VERSION ""

NS_ :

BS_:

BU_: EPS ESP_ECU BCM VCU MPC_CAM ADAS_ECU MCU BSD

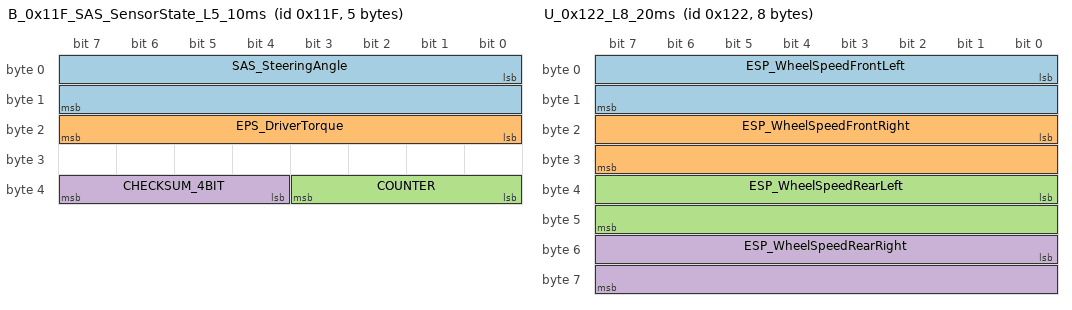
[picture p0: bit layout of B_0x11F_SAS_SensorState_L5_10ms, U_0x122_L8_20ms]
BO_ 287 B_0x11F_SAS_SensorState_L5_10ms: 5 EPS
 SG_ SAS_SteeringAngle : 0|16@1- (0.1,0) [-780|780] "deg" MCU,ADAS_ECU
 SG_ EPS_DriverTorque : 16|8@1+ (1,0) [0|255] "" MCU,ADAS_ECU
 SG_ COUNTER : 35|4@0+ (1,0) [0|15] "" MCU
 SG_ CHECKSUM_4BIT : 39|4@0+ (1,0) [0|15] "" MCU

BO_ 290 U_0x122_L8_20ms: 8 ESP_ECU
 SG_ ESP_WheelSpeedFrontLeft : 0|16@1+ (0.1,0) [0|6553.5] "kph" MCU,ADAS_ECU
 SG_ ESP_WheelSpeedFrontRight : 16|16@1+ (0.1,0) [0|6553.5] "kph" MCU,ADAS_ECU
 SG_ ESP_WheelSpeedRearLeft : 32|16@1+ (0.1,0) [0|6553.5] "kph" MCU,ADAS_ECU
 SG_ ESP_WheelSpeedRearRight : 48|16@1+ (0.1,0) [0|6553.5] "kph" MCU,ADAS_ECU

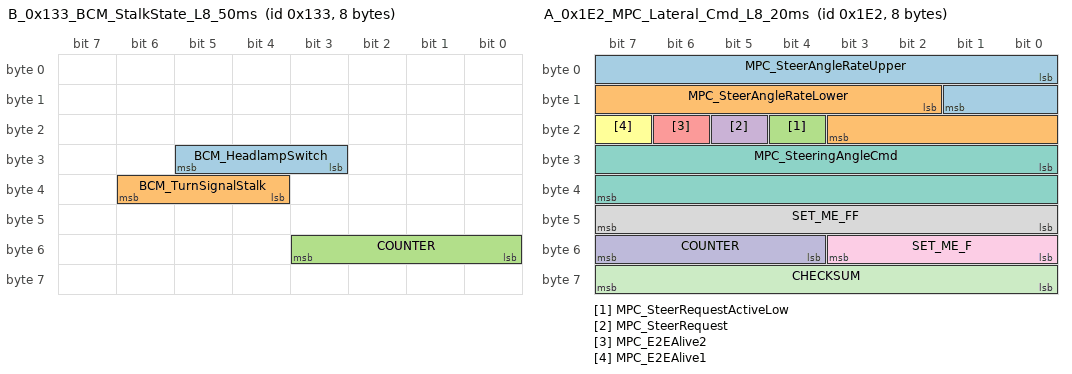
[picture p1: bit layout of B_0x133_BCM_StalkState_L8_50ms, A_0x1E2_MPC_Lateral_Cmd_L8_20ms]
BO_ 307 B_0x133_BCM_StalkState_L8_50ms: 8 BCM
 SG_ BCM_HeadlampSwitch : 27|3@1+ (1,0) [0|7] "" MCU
 SG_ BCM_TurnSignalStalk : 36|3@1+ (1,0) [0|7] "" MCU
 SG_ COUNTER : 48|4@1+ (1,0) [0|15] "" MCU

BO_ 482 A_0x1E2_MPC_Lateral_Cmd_L8_20ms: 8 ADAS_ECU
 SG_ MPC_SteerAngleRateUpper : 0|10@1- (1,0) [-512|511] "" EPS
 SG_ MPC_SteerAngleRateLower : 10|10@1- (1,0) [-512|511] "" EPS
 SG_ MPC_SteerRequestActiveLow : 20|1@1+ (1,0) [0|1] "" EPS
 SG_ MPC_SteerRequest : 21|1@1+ (1,0) [0|1] "" EPS
 SG_ MPC_E2EAlive2 : 22|1@1+ (1,0) [0|1] "" EPS
 SG_ MPC_E2EAlive1 : 23|1@1+ (1,0) [0|1] "" EPS
 SG_ MPC_SteeringAngleCmd : 24|16@1- (0.1,0) [-3276.8|3276.7] "deg" EPS
 SG_ SET_ME_FF : 40|8@1+ (1,0) [0|255] "" EPS
 SG_ SET_ME_F : 48|4@1+ (1,0) [0|15] "" EPS
 SG_ COUNTER : 52|4@1+ (1,0) [0|15] "" EPS
 SG_ CHECKSUM : 56|8@1+ (1,0) [0|255] "" EPS

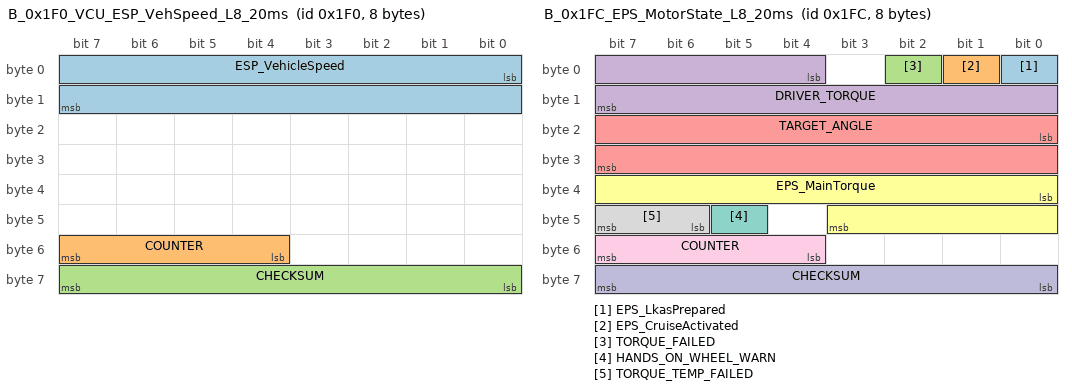
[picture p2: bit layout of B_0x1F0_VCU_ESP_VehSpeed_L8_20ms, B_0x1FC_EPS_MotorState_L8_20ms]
BO_ 496 B_0x1F0_VCU_ESP_VehSpeed_L8_20ms: 8 ESP_ECU
 SG_ ESP_VehicleSpeed : 0|16@1+ (0.07142857,0) [0|4681.16505] "kph" MCU
 SG_ COUNTER : 55|4@0+ (1,0) [0|15] "" MCU
 SG_ CHECKSUM : 56|8@1+ (1,0) [0|255] "" MCU

BO_ 508 B_0x1FC_EPS_MotorState_L8_20ms: 8 EPS
 SG_ EPS_LkasPrepared : 0|1@1+ (1,0) [0|1] "" MCU,ADAS_ECU
 SG_ EPS_CruiseActivated : 1|1@1+ (1,0) [0|1] "" MCU,ADAS_ECU
 SG_ TORQUE_FAILED : 2|1@1+ (1,0) [0|1] "" MCU,ADAS_ECU
 SG_ DRIVER_TORQUE : 4|12@1- (0.1,0) [-204.8|204.7] "Nm" MCU,ADAS_ECU
 SG_ TARGET_ANGLE : 16|16@1- (0.1,0) [-3276.8|3276.7] "deg" MCU,ADAS_ECU
 SG_ EPS_MainTorque : 32|12@1- (1,0) [-2048|2047] "" MCU,ADAS_ECU
 SG_ HANDS_ON_WHEEL_WARN : 45|1@1+ (1,0) [0|1] "" MCU,ADAS_ECU
 SG_ TORQUE_TEMP_FAILED : 46|2@1+ (1,0) [0|3] "" MCU,ADAS_ECU
 SG_ COUNTER : 52|4@1+ (1,0) [0|15] "" MCU
 SG_ CHECKSUM : 56|8@1+ (1,0) [0|255] "" MCU

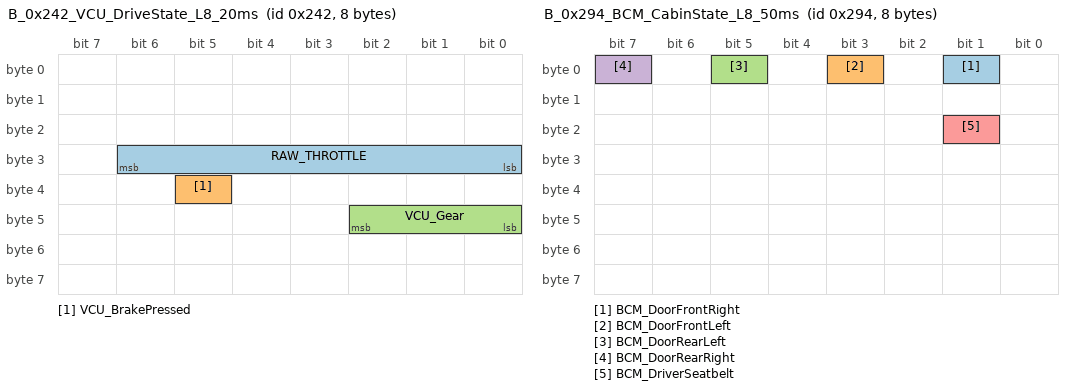
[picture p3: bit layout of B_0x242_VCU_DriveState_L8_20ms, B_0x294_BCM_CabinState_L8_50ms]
BO_ 578 B_0x242_VCU_DriveState_L8_20ms: 8 VCU
 SG_ RAW_THROTTLE : 24|7@1+ (1,0) [0|127] "" MCU
 SG_ VCU_BrakePressed : 37|1@1+ (1,0) [0|1] "" MCU,ADAS_ECU
 SG_ VCU_Gear : 40|3@1+ (1,0) [0|7] "" MCU

BO_ 660 B_0x294_BCM_CabinState_L8_50ms: 8 BCM
 SG_ BCM_DoorFrontRight : 1|1@1+ (1,0) [0|1] "" MCU
 SG_ BCM_DoorFrontLeft : 3|1@1+ (1,0) [0|1] "" MCU
 SG_ BCM_DoorRearLeft : 5|1@1+ (1,0) [0|1] "" MCU
 SG_ BCM_DoorRearRight : 7|1@1+ (1,0) [0|1] "" MCU
 SG_ BCM_DriverSeatbelt : 17|1@1+ (1,0) [0|1] "" MCU

BO_ 790 A_0x316_MPC_MpcState_L8_20ms: 8 MPC_CAM
 SG_ AUTO_LIGHT : 1|2@0+ (1,0) [0|3] "" XXX
 SG_ MPC_HudPt1 : 2|2@1+ (1,0) [0|3] "" MCU
 SG_ MPC_LeftLaneState : 4|2@1+ (1,0) [0|3] "" MCU
 SG_ MPC_LksMode : 6|2@1+ (1,0) [0|3] "" MCU
 SG_ MPC_HudPt2 : 8|2@1+ (1,0) [0|3] "" MCU
 SG_ MPC_HandsOnWheelRequest : 10|1@1+ (1,0) [0|1] "" MCU
 SG_ MPC_TjaIcaState : 11|4@1+ (1,0) [0|15] "" MCU
 SG_ HMA_ON_OFF : 15|1@0+ (1,0) [0|1] "" MCU
 SG_ MPC_LkasOutput : 16|11@1- (1,0) [-1024|1023] "" MCU
 SG_ MPC_LkasRequestPrepare : 27|1@1+ (1,0) [0|1] "" MCU
 SG_ MPC_LkasActive : 28|1@1+ (1,0) [0|1] "" MCU
 SG_ MPC_SlaState : 29|3@1+ (1,0) [0|7] "" MCU
 SG_ MPC_HudPt3 : 32|2@1+ (1,0) [0|3] "" MCU
 SG_ MPC_RightLaneState : 34|2@1+ (1,0) [0|3] "" MCU
 SG_ MPC_LkasState : 36|4@1+ (1,0) [0|15] "" MCU
 SG_ MPC_SpeedLimitValue : 40|8@1+ (5,-5) [-5|1270] "kph" MCU
 SG_ LDSW_TYPE : 49|2@0+ (1,0) [0|3] "" MCU
 SG_ MPC_HudPt4 : 50|2@1+ (1,0) [0|3] "" MCU
 SG_ COUNTER : 52|4@1+ (1,0) [0|15] "" MCU
 SG_ CHECKSUM : 56|8@1+ (1,0) [0|255] "" MCU

BO_ 813 B_0x32D_HUD_AdasState_L8_20ms: 8 ADAS_ECU
 SG_ VCU_ACCSetSpeed : 0|8@1+ (0.5,0) [0|127.5] "kph" MCU
 SG_ VCU_ACCSetDistance : 10|3@1+ (1,0) [0|7] "" MCU
 SG_ VCU_ACCState : 19|3@1+ (1,0) [0|7] "" MCU
 SG_ ACC_ON2 : 20|1@0+ (1,0) [0|1] "" MCU
 SG_ ACC_ON1 : 22|1@0+ (1,0) [0|1] "" MCU
 SG_ SET_ME_XFF : 47|8@0+ (1,0) [0|255] "" MCU
 SG_ COUNTER : 48|4@1+ (1,0) [0|15] "" MCU
 SG_ SET_ME_XF : 55|4@0+ (1,0) [0|15] "" MCU
 SG_ CHECKSUM : 56|8@1+ (1,0) [0|255] "" MCU

BO_ 814 A_0x32E_MPC_Long_Cmd_L8_20ms: 8 ADAS_ECU
 SG_ MPC_AccelerationCmd : 0|8@1+ (0.05,-5) [-5|7.75] "m/s^2" MCU
 SG_ MPC_AccOnPrimary : 9|1@1+ (1,0) [0|1] "" MCU
 SG_ SET_ME_25_1 : 10|6@1+ (1,0) [0|63] "" MCU
 SG_ MPC_AccOnSecondary : 17|1@1+ (1,0) [0|1] "" MCU
 SG_ SET_ME_25_2 : 18|6@1+ (1,0) [0|63] "" MCU
 SG_ MPC_ComfortDecelFactor : 24|4@1+ (1,0) [0|15] "" MCU
 SG_ SET_ME_X8 : 28|4@1+ (1,0) [0|15] "" MCU
 SG_ MPC_ComfortAccelFactor : 32|4@1+ (1,0) [0|15] "" MCU
 SG_ MPC_CommandRequestActiveLow : 36|1@1+ (1,0) [0|1] "" MCU
 SG_ SET_ME_1 : 38|1@1+ (1,0) [0|1] "" MCU
 SG_ MPC_StandstillResume : 39|1@1+ (1,0) [0|1] "" MCU
 SG_ MPC_StandstillState : 40|1@1+ (1,0) [0|1] "" MCU
 SG_ MPC_AccRequestNotStandstill : 43|1@1+ (1,0) [0|1] "" MCU
 SG_ MPC_AccControllableOn : 44|1@1+ (1,0) [0|1] "" MCU
 SG_ MPC_AccOverrideStandstill : 45|1@1+ (1,0) [0|1] "" MCU
 SG_ COUNTER : 48|4@1+ (1,0) [0|15] "" MCU
 SG_ SET_ME_XF : 55|4@0+ (1,0) [0|15] "" MCU
 SG_ CHECKSUM : 56|8@1+ (1,0) [0|255] "" MCU

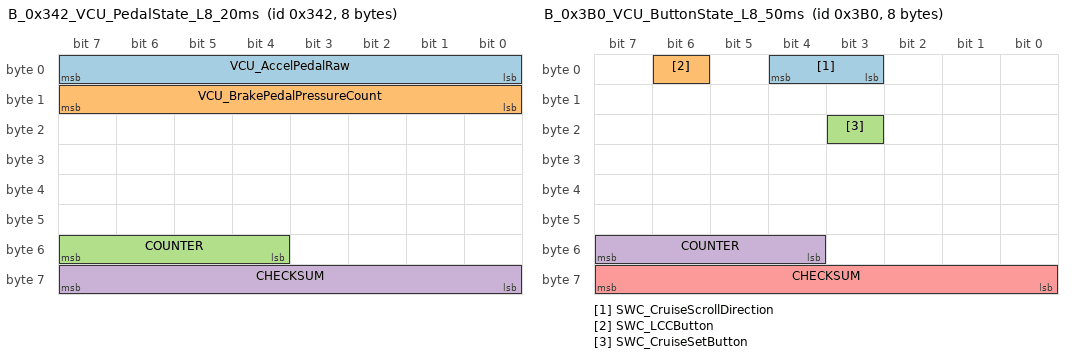
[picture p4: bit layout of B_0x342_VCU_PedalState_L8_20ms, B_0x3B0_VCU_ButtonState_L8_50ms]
BO_ 834 B_0x342_VCU_PedalState_L8_20ms: 8 VCU
 SG_ VCU_AccelPedalRaw : 0|8@1+ (1,0) [0|255] "" MCU
 SG_ VCU_BrakePedalPressureCount : 8|8@1+ (1,0) [0|255] "count" MCU
 SG_ COUNTER : 55|4@0+ (1,0) [0|15] "" MCU
 SG_ CHECKSUM : 56|8@1+ (1,0) [0|255] "" MCU

BO_ 944 B_0x3B0_VCU_ButtonState_L8_50ms: 8 MCU
 SG_ SWC_CruiseScrollDirection : 3|2@1+ (1,0) [0|3] "" MCU
 SG_ SWC_LCCButton : 6|1@1+ (1,0) [0|1] "" MCU
 SG_ SWC_CruiseSetButton : 19|1@1+ (1,0) [0|1] "" MCU
 SG_ COUNTER : 55|4@0+ (1,0) [0|15] "" MCU
 SG_ CHECKSUM : 63|8@0+ (1,0) [0|255] "" MCU

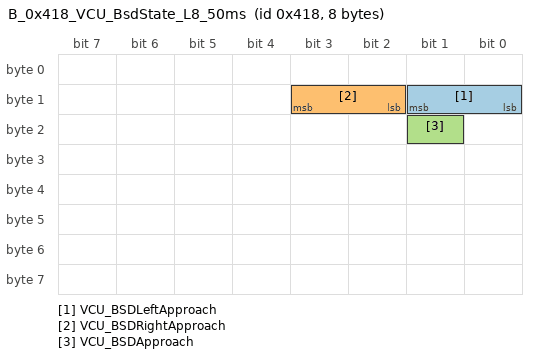
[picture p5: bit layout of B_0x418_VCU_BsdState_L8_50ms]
BO_ 1048 B_0x418_VCU_BsdState_L8_50ms: 8 BSD
 SG_ VCU_BSDLeftApproach : 8|2@1+ (1,0) [0|3] "" MCU,ADAS_ECU
 SG_ VCU_BSDRightApproach : 10|2@1+ (1,0) [0|3] "" MCU,ADAS_ECU
 SG_ VCU_BSDApproach : 17|1@1+ (1,0) [0|1] "" MCU,ADAS_ECU

CM_ "Message and signal names follow the tc275_freertos/dev-BYD_ATTO3 and local
BYD_Atto3 CANape convention (`{A|B|C|U}_0xNNN_Function_Ln_period`), not the
community shemps/byd-atto3-openpilot-port fork. Two exceptions are required by
opendbc/can/dbc.py:set_signal_type, which attaches counter/checksum semantics
by matching the literal signal names `COUNTER` and `CHECKSUM` — the canonical
per-message names (e.g. `MPC_RollingCounter_1E2`) cannot be used here. Fields
still under a community/reference-only name have not been confirmed bit-
identical against the local CANape/tc275 capture; see
nagaspilot/docs/BYD_REFERENCE_PARITY_AUDIT.md and
~/panda/BYD_Atto3/DOC/community_port_comparison.md before renaming them.";
CM_ BO_ 287 "EPS steering wheel angle + driver torque. Validated: angle range plausible, EPS_DriverTorque stays near 0 when hands-off.";
CM_ BO_ 290 "Per-wheel speed from ESP (FL/FR/BL/BR). Scale 0.1 kph/bit. Use ESP_VehicleSpeed (0x1F0) for the aggregated filtered value openpilot consumes.";
CM_ BO_ 307 "Turn signal / stalk info. Bit layout matches the tc275_freertos dev/BYD_ATTO3 firmware (DBC/byd_atto3.c, case 0x133), which reads BCM_TurnSignalStalk on the real car; the prior community LEFT_BLINKER/RIGHT_BLINKER bit-flag decode at a different bit position has been replaced.";
CM_ BO_ 482 "Lateral steering command sent by MPC camera/ADAS ECU to EPS. Blocked by panda on bus 2; panda injects its own on bus 0.";
CM_ BO_ 496 "Wheel speed (cleaned average). Validated: 0-127 km/h matching driving speed.";
CM_ BO_ 508 "Column steering torque from EPS. TORQUE_FAILED, DRIVER_TORQUE, TARGET_ANGLE, HANDS_ON_WHEEL_WARN and TORQUE_TEMP_FAILED have no confirmed counterpart in the local CANape capture; kept as community-sourced telemetry, not safety inputs.";
CM_ BO_ 578 "Drivetrain state: gear, brake pressed, raw throttle. Bit layout (RAW_THROTTLE 24|7, VCU_BrakePressed 37|1, VCU_Gear 40|3, all Intel) matches the tc275_freertos dev/BYD_ATTO3 firmware (DBC/byd_atto3.c, case 0x242).";
CM_ BO_ 660 "Body/meter cluster: doors + seatbelt. Bit layout confirmed against the tc275_freertos dev/BYD_ATTO3 firmware (DBC/byd_atto3.c, case 0x294); all fields Intel.";
CM_ BO_ 790 "LKAS HUD ADAS message from camera. Blocked by panda on bus 2; panda re-injects. MPC_HandsOnWheelRequest, MPC_LkasActive and MPC_LkasState are firmware-confirmed (DBC/byd_atto3.c, case 0x316); the firmware also reads an undocumented bit 35 (handsOffDetected) that overlaps MPC_RightLaneState's low bit — not yet reconciled. AUTO_LIGHT, HMA_ON_OFF and LDSW_TYPE still use a different bit offset/endianness with no firmware witness and are kept unrenamed. HudPt1-4 name previously-unnamed bits so a decode/repack round-trips byte-exact: the modules validate this frame's full bit pattern and fail-safe (latched DTCs) if a regenerated frame flips any bit. On-car MPC_HudPt3 bit 32 is constant 1; an unnamed bit packs as 0.";
CM_ BO_ 813 "ACC HUD ADAS message (cruise set speed, distance, ACC state). VCU_ACCSetSpeed, VCU_ACCSetDistance and VCU_ACCState are firmware-confirmed (DBC/byd_atto3.c, case 0x32D); the secondary ACC_ON1/ACC_ON2 flags are not read by that firmware and remain unconfirmed.";
CM_ BO_ 814 "ACC acceleration command from ADAS ECU. Blocked by panda on bus 2 when OP longitudinal active. Bit layout firmware-confirmed (DBC/byd_atto3.c, case 0x32E TX) except SET_ME_XF, which that code does not write.";
CM_ BO_ 834 "Gas/brake pedal state. Bit layout and raw (unscaled) unit match the tc275_freertos dev/BYD_ATTO3 firmware (DBC/byd_atto3.c, case 0x342); VCU_AccelPedalRaw > 10 is the tested gas-pressed threshold (also used raw in opendbc/safety/modes/byd.h). Percent/normalized conversion is applied downstream in carstate.py, not in this scale.";
CM_ BO_ 944 "Steering-wheel cruise control buttons. Bit layout matches the tc275_freertos dev/BYD_ATTO3 firmware (DBC/byd_atto3.c, case 0x3B0), which only decodes SWC_CruiseScrollDirection, SWC_LCCButton and SWC_CruiseSetButton on the real car; the prior community SET_BTN/RES_BTN/LKAS_ON_BTN/distance-button fields were unvalidated and have been dropped.";
CM_ BO_ 1048 "Blind-spot approach state. Bit layout (VCU_BSDLeftApproach 8|2, VCU_BSDRightApproach 10|2, VCU_BSDApproach 17|1, all Intel) matches the tc275_freertos dev/BYD_ATTO3 firmware (DBC/byd_atto3.c, case 0x418).";
VAL_ 307 BCM_TurnSignalStalk 0 "OFF" 1 "LEFT" 2 "RIGHT";
VAL_ 508 TORQUE_TEMP_FAILED 1 "TooLarge" 2 "TooFast" 3 "Both";
VAL_ 578 VCU_Gear 4 "D" 2 "R" 3 "N" 1 "P";
VAL_ 790 AUTO_LIGHT 1 "OFF" 2 "ON";
VAL_ 790 MPC_LeftLaneState 0 "OFF" 1 "GREEN" 2 "ORANGE";
VAL_ 790 MPC_LksMode 0 "OFF" 1 "DIVERGE" 2 "KEEPING" 3 "ALL";
VAL_ 790 MPC_TjaIcaState 0 "OFF" 1 "PASSIVE" 2 "ACTIVE1" 3 "ACTIVE2" 4 "FAULT";
VAL_ 790 MPC_SlaState 0 "OFF" 1 "FUSION_MODE" 2 "VISION_MODE" 3 "NV_ONLY_MODE" 4 "DEFECT";
VAL_ 790 MPC_RightLaneState 0 "OFF" 1 "GREEN" 2 "ORANGE";
VAL_ 790 MPC_LkasState 2 "ACTIVE" 1 "OFF";
VAL_ 790 LDSW_TYPE 0 "VIBRATE" 1 "SOUND" 2 "ALL";
VAL_ 813 VCU_ACCSetDistance 4 "4bar" 3 "3bar" 2 "2bar" 1 "1bar";
VAL_ 813 VCU_ACCState 0 "OFF" 2 "ACC_ON" 3 "ACC_ACTIVE" 5 "FORCE_ACCEL" 7 "ERROR";
